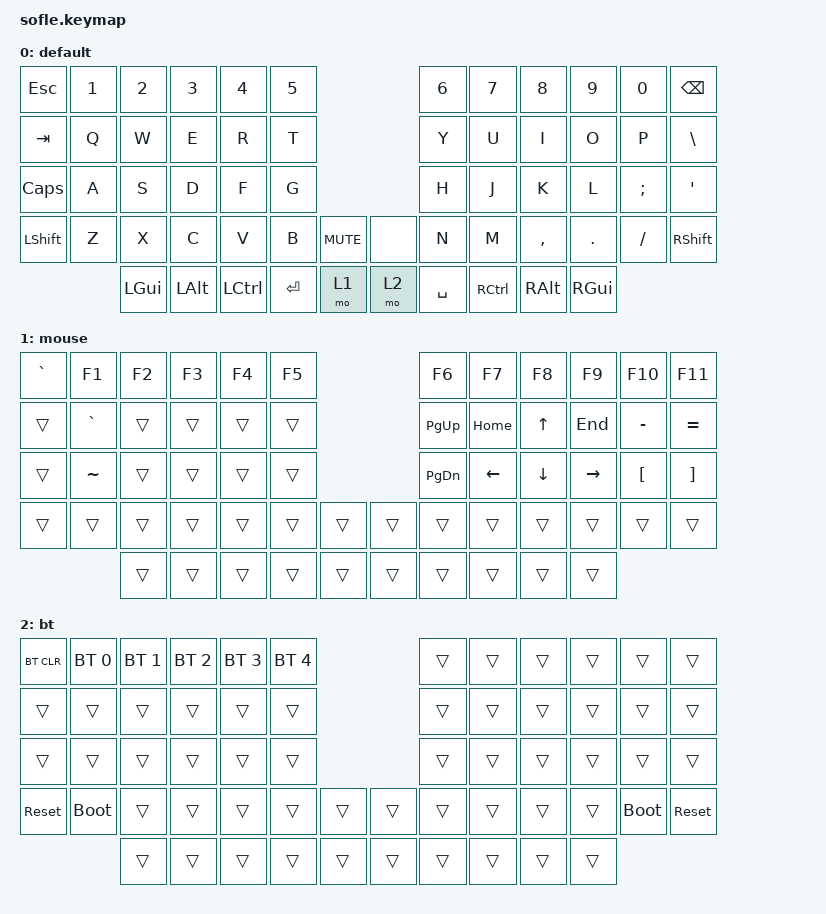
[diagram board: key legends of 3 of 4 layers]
#define ZMK_POINTING_DEFAULT_MOVE_VAL 1200  // 600
#define ZMK_POINTING_DEFAULT_SCRL_VAL 25   // 10

#include <behaviors.dtsi>
#include <dt-bindings/zmk/keys.h>
#include <dt-bindings/zmk/bt.h>
#include <dt-bindings/zmk/rgb.h>
#include <dt-bindings/zmk/outputs.h>
#include <dt-bindings/zmk/ext_power.h>
#include <dt-bindings/zmk/pointing.h>
#include <input/processors.dtsi>

&mmv_input_listener { input-processors = <&zip_xy_scaler 2 1>; };
&msc_input_listener { input-processors = <&zip_scroll_scaler 2 1>; };

&msc {
    acceleration-exponent = <1>;
    time-to-max-speed-ms = <100>;
    delay-ms = <0>;
};

&mmv {
    time-to-max-speed-ms = <500>;
    acceleration-exponent = <1>;
    trigger-period-ms = <16>;
};

/ {
    scroll_encoder: scroll_encoder {
        compatible = "zmk,behavior-sensor-rotate";
        #sensor-binding-cells = <0>;
        bindings = <&msc SCRL_DOWN>, <&msc SCRL_UP>;
        tap-ms = <100>;
    };

    keymap {
        compatible = "zmk,keymap";

        default_layer {
            display-name = "default";
            bindings = <
&kp ESC    &kp N1   &kp N2   &kp N3   &kp N4   &kp N5                     &kp N6   &kp N7   &kp N8   &kp N9    &kp N0   &kp BSPC
&kp TAB    &kp Q    &kp W    &kp E    &kp R    &kp T                      &kp Y    &kp U    &kp I    &kp O     &kp P    &kp BSLH
&kp CAPS   &kp A    &kp S    &kp D    &kp F    &kp G                      &kp H    &kp J    &kp K    &kp L     &kp SEMI &kp APOS
&kp LSHFT  &kp Z    &kp X    &kp C    &kp V    &kp B    &kp C_MUTE &none &kp N    &kp M    &kp COMMA &kp DOT  &kp FSLH &kp RSHFT
                    &kp LGUI &kp LALT &kp LCTRL &kp RET  &mo 1     &mo 2  &kp SPACE &kp RCTRL &kp RALT &kp RGUI
            >;
            sensor-bindings = <&inc_dec_kp C_VOLUME_UP C_VOL_DN>;
        };

        mouse_layer {
            display-name = "mouse";
            bindings = <
&kp GRAVE  &kp F1    &kp F2    &kp F3    &kp F4    &kp F5                      &kp F6    &kp F7   &kp F8   &kp F9    &kp F10   &kp F11
&trans     &kp GRAVE &trans    &trans    &trans    &trans                      &kp PG_UP &kp HOME &kp UP   &kp END   &kp MINUS &kp EQUAL
&trans     &kp TILDE &trans    &trans    &trans    &trans                      &kp PG_DN &kp LEFT &kp DOWN &kp RIGHT &kp LBKT  &kp RBKT
&trans     &trans    &trans    &trans    &trans    &trans    &trans    &trans  &trans    &trans   &trans   &trans    &trans    &trans
                     &trans    &trans    &trans    &trans    &trans    &trans  &trans    &trans   &trans   &trans
            >;
            sensor-bindings = <&scroll_encoder>;
        };

        bt_layer {
            display-name = "bt";
            bindings = <
&bt BT_CLR   &bt BT_SEL 0 &bt BT_SEL 1 &bt BT_SEL 2 &bt BT_SEL 3 &bt BT_SEL 4             &trans   &trans   &trans   &trans    &trans   &trans
&trans       &trans       &trans       &trans       &trans       &trans                     &trans   &trans   &trans   &trans    &trans   &trans
&trans       &trans       &trans       &trans       &trans       &trans                     &trans   &trans   &trans   &trans    &trans   &trans
&sys_reset   &bootloader  &trans       &trans       &trans       &trans    &trans  &trans   &trans   &trans   &trans   &trans    &bootloader &sys_reset
                         &trans       &trans       &trans       &trans    &trans  &trans   &trans   &trans   &trans   &trans
            >;
            sensor-bindings = <&scroll_encoder>;
        };

        adjust_layer {
            display-name = "adjust";
            bindings = <
&trans  &trans  &trans  &trans  &trans  &trans    &trans  &trans  &trans  &trans  &trans  &trans  &trans
&trans  &trans  &trans  &trans  &trans  &trans    &trans  &trans  &trans  &trans  &trans  &trans  &trans
&trans  &trans  &trans  &trans  &trans  &trans    &trans  &trans  &trans  &trans  &trans  &trans  &trans
&trans  &trans  &trans  &trans  &trans  &trans    &trans  &trans  &trans  &trans  &trans  &trans  &trans
&trans  &trans  &trans  &trans  &trans  &trans    &trans  &trans  &trans  &trans  &trans  &trans
            >;
        };
    };
};
